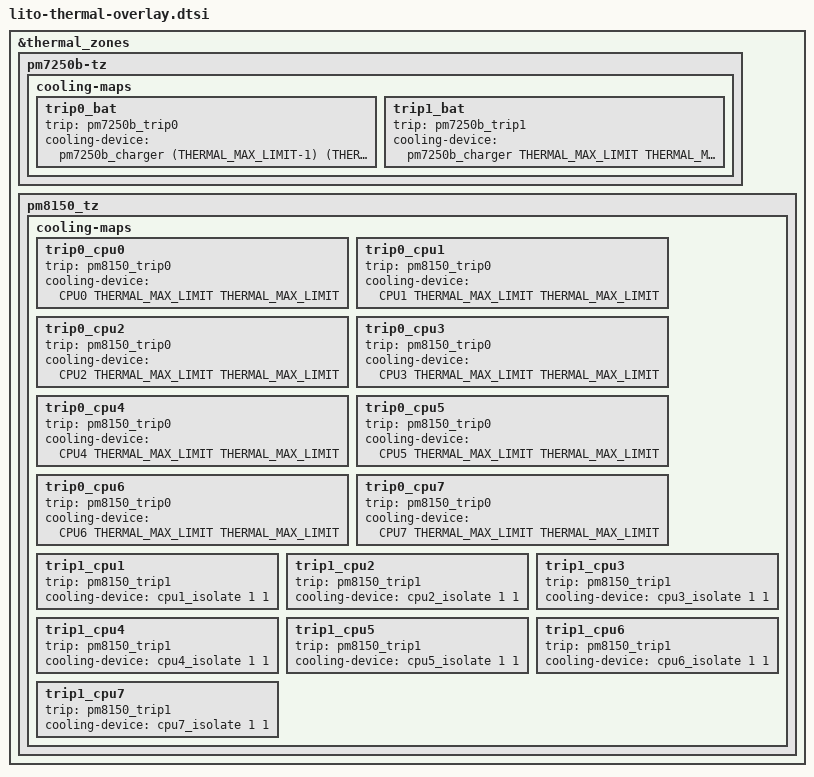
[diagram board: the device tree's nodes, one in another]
#include <dt-bindings/thermal/thermal.h>

&thermal_zones {
	pm7250b-tz {
		cooling-maps {
			trip0_bat {
				trip = <&pm7250b_trip0>;
				cooling-device =
					<&pm7250b_charger (THERMAL_MAX_LIMIT-1)
						(THERMAL_MAX_LIMIT-1)>;
			};

			trip1_bat {
				trip = <&pm7250b_trip1>;
				cooling-device =
					<&pm7250b_charger THERMAL_MAX_LIMIT
						THERMAL_MAX_LIMIT>;
			};
		};
	};

	pm8150_tz {
		cooling-maps {
			trip0_cpu0 {
				trip = <&pm8150_trip0>;
				cooling-device =
					<&CPU0 THERMAL_MAX_LIMIT
						THERMAL_MAX_LIMIT>;
			};

			trip0_cpu1 {
				trip = <&pm8150_trip0>;
				cooling-device =
					<&CPU1 THERMAL_MAX_LIMIT
						THERMAL_MAX_LIMIT>;
			};

			trip0_cpu2 {
				trip = <&pm8150_trip0>;
				cooling-device =
					<&CPU2 THERMAL_MAX_LIMIT
						THERMAL_MAX_LIMIT>;
			};

			trip0_cpu3 {
				trip = <&pm8150_trip0>;
				cooling-device =
					<&CPU3 THERMAL_MAX_LIMIT
						THERMAL_MAX_LIMIT>;
			};

			trip0_cpu4 {
				trip = <&pm8150_trip0>;
				cooling-device =
					<&CPU4 THERMAL_MAX_LIMIT
						THERMAL_MAX_LIMIT>;
			};

			trip0_cpu5 {
				trip = <&pm8150_trip0>;
				cooling-device =
					<&CPU5 THERMAL_MAX_LIMIT
						THERMAL_MAX_LIMIT>;
			};

			trip0_cpu6 {
				trip = <&pm8150_trip0>;
				cooling-device =
					<&CPU6 THERMAL_MAX_LIMIT
						THERMAL_MAX_LIMIT>;
			};

			trip0_cpu7 {
				trip = <&pm8150_trip0>;
				cooling-device =
					<&CPU7 THERMAL_MAX_LIMIT
						THERMAL_MAX_LIMIT>;
			};

			trip1_cpu1 {
				trip = <&pm8150_trip1>;
				cooling-device = <&cpu1_isolate 1 1>;
			};

			trip1_cpu2 {
				trip = <&pm8150_trip1>;
				cooling-device = <&cpu2_isolate 1 1>;
			};

			trip1_cpu3 {
				trip = <&pm8150_trip1>;
				cooling-device = <&cpu3_isolate 1 1>;
			};

			trip1_cpu4 {
				trip = <&pm8150_trip1>;
				cooling-device = <&cpu4_isolate 1 1>;
			};

			trip1_cpu5 {
				trip = <&pm8150_trip1>;
				cooling-device = <&cpu5_isolate 1 1>;
			};

			trip1_cpu6 {
				trip = <&pm8150_trip1>;
				cooling-device = <&cpu6_isolate 1 1>;
			};

			trip1_cpu7 {
				trip = <&pm8150_trip1>;
				cooling-device = <&cpu7_isolate 1 1>;
			};
		};
	};
};
